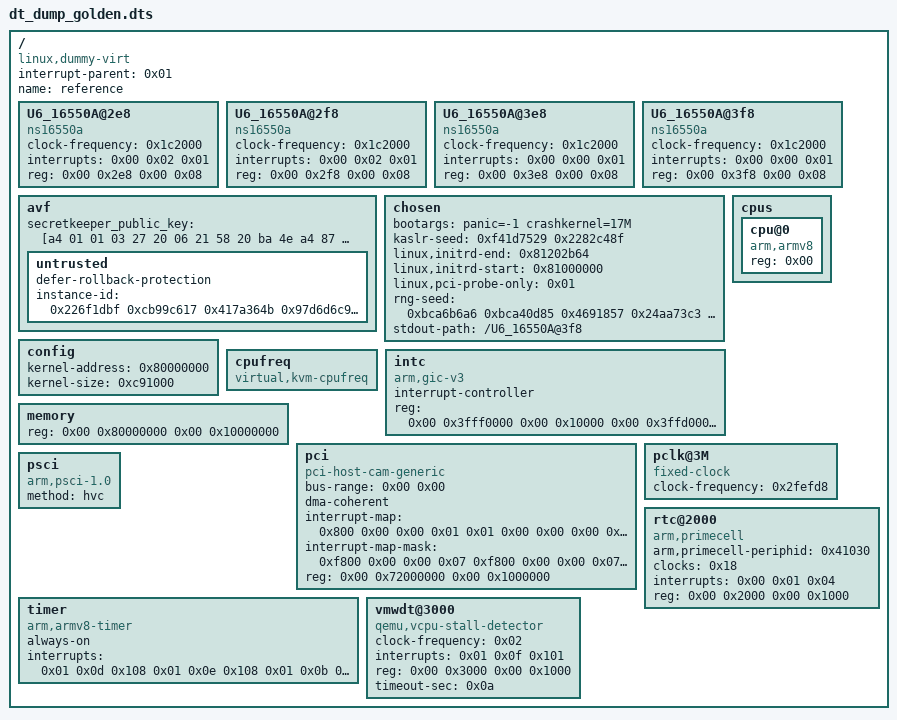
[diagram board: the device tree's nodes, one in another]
/dts-v1/;

/ {
	#address-cells = <0x02>;
	#size-cells = <0x02>;
	compatible = "linux,dummy-virt";
	interrupt-parent = <0x01>;
	name = "reference";

	U6_16550A@2e8 {
		clock-frequency = <0x1c2000>;
		compatible = "ns16550a";
		interrupts = <0x00 0x02 0x01>;
		reg = <0x00 0x2e8 0x00 0x08>;
	};

	U6_16550A@2f8 {
		clock-frequency = <0x1c2000>;
		compatible = "ns16550a";
		interrupts = <0x00 0x02 0x01>;
		reg = <0x00 0x2f8 0x00 0x08>;
	};

	U6_16550A@3e8 {
		clock-frequency = <0x1c2000>;
		compatible = "ns16550a";
		interrupts = <0x00 0x00 0x01>;
		reg = <0x00 0x3e8 0x00 0x08>;
	};

	U6_16550A@3f8 {
		clock-frequency = <0x1c2000>;
		compatible = "ns16550a";
		interrupts = <0x00 0x00 0x01>;
		reg = <0x00 0x3f8 0x00 0x08>;
	};

	__symbols__ {
		intc = "/intc";
	};

	avf {
		secretkeeper_public_key = [a4 01 01 03 27 20 06 21 58 20 ba 4e a4 87 1a 9e 8e 3b a9 15 f4 7c 02 89 87 bd c4 70 d7 b8 48 91 a1 09 38 83 20 c9 85 58 7d a8];

		untrusted {
			defer-rollback-protection;
			instance-id = <0x226f1dbf 0xcb99c617 0x417a364b 0x97d6d6c9 0x278098e 0x1ef0198d 0x5db1a290 0x601513f5 0xddac8bb5 0x9b1dad87 0xecfe9c66 0x7a97e57e 0x4a02c804 0x455207f7 0x766f9490 0x94f4c30d>;
		};
	};

	chosen {
		bootargs = "panic=-1 crashkernel=17M";
		kaslr-seed = <0xf41d7529 0x2282c48f>;
		linux,initrd-end = <0x81202b64>;
		linux,initrd-start = <0x81000000>;
		linux,pci-probe-only = <0x01>;
		rng-seed = <0xbca6b6a6 0xbca40d85 0x4691857 0x24aa73c3 0x2acd4d64 0x978184a3 0x34fedccc 0x18c5858e 0x89a0f436 0xa873b57e 0xbabdc555 0x94611b2f 0xf5c00896 0xaefc540 0xd50b30d3 0x444c020e 0xa55029f1 0xb589c657 0x9704b342 0xe3bcc3cd 0x128c7dac 0x1f0ee287 0xa447ac89 0x4a78e56 0x324b73b9 0x3a83eed3 0x771efcf1 0x7a7cc6bd 0xcd5912fc 0x28163d1b 0x38764934 0xb02ad6f8 0x89666e5c 0x92c6e112 0xb55f4739 0xa321da86 0x1726fabb 0x1b628c1c 0x5a3c1c5b 0xa5c1a2cb 0xace0e1ae 0x7a86e528 0xcafcdc24 0x73a6a268 0x72fbb9fc 0xca52c7c5 0xf540b2e9 0x14684a4c 0xfc88a4e 0x7dddde5d 0x22994ddd 0xf4a79d13 0x7149e07d 0xc5de64bd 0x50b35637 0xaef6cd2b 0x4210696f 0xc948145e 0xe4cce026 0xf50cbd5e 0xfcdf5ae5 0xc0120fe7 0x62b53fc6 0x31006531>;
		stdout-path = "/U6_16550A@3f8";
	};

	config {
		kernel-address = <0x80000000>;
		kernel-size = <0xc91000>;
	};

	cpufreq {
		compatible = "virtual,kvm-cpufreq";
	};

	cpus {
		#address-cells = <0x01>;
		#size-cells = <0x00>;

		cpu@0 {
			compatible = "arm,armv8";
			device_type = "cpu";
			phandle = <0x100>;
			reg = <0x00>;
		};
	};

	intc {
		#address-cells = <0x02>;
		#interrupt-cells = <0x03>;
		#size-cells = <0x02>;
		compatible = "arm,gic-v3";
		interrupt-controller;
		phandle = <0x01>;
		reg = <0x00 0x3fff0000 0x00 0x10000 0x00 0x3ffd0000 0x00 0x20000>;
	};

	memory {
		device_type = "memory";
		reg = <0x00 0x80000000 0x00 0x10000000>;
	};

	pci {
		#address-cells = <0x03>;
		#interrupt-cells = <0x01>;
		#size-cells = <0x02>;
		bus-range = <0x00 0x00>;
		compatible = "pci-host-cam-generic";
		device_type = "pci";
		dma-coherent;
		interrupt-map = <0x800 0x00 0x00 0x01 0x01 0x00 0x00 0x00 0x04 0x04 0x1000 0x00 0x00 0x01 0x01 0x00 0x00 0x00 0x05 0x04 0x1800 0x00 0x00 0x01 0x01 0x00 0x00 0x00 0x06 0x04 0x2000 0x00 0x00 0x01 0x01 0x00 0x00 0x00 0x07 0x04 0x2800 0x00 0x00 0x01 0x01 0x00 0x00 0x00 0x08 0x04 0x3000 0x00 0x00 0x01 0x01 0x00 0x00 0x00 0x09 0x04 0x3800 0x00 0x00 0x01 0x01 0x00 0x00 0x00 0x0a 0x04 0x4000 0x00 0x00 0x01 0x01 0x00 0x00 0x00 0x0b 0x04 0x4800 0x00 0x00 0x01 0x01 0x00 0x00 0x00 0x0c 0x04>;
		interrupt-map-mask = <0xf800 0x00 0x00 0x07 0xf800 0x00 0x00 0x07 0xf800 0x00 0x00 0x07 0xf800 0x00 0x00 0x07 0xf800 0x00 0x00 0x07 0xf800 0x00 0x00 0x07 0xf800 0x00 0x00 0x07 0xf800 0x00 0x00 0x07 0xf800 0x00 0x00 0x07>;
		ranges = <0x3000000 0x00 0x70000000 0x00 0x70000000 0x00 0x2000000 0x43000000 0x00 0x90800000 0x00 0x90800000 0xff 0x6f800000>;
		reg = <0x00 0x72000000 0x00 0x1000000>;
	};

	pclk@3M {
		#clock-cells = <0x00>;
		clock-frequency = <0x2fefd8>;
		compatible = "fixed-clock";
		phandle = <0x18>;
	};

	psci {
		compatible = "arm,psci-1.0\0arm,psci-0.2";
		method = "hvc";
	};

	rtc@2000 {
		arm,primecell-periphid = <0x41030>;
		clock-names = "apb_pclk";
		clocks = <0x18>;
		compatible = "arm,primecell";
		interrupts = <0x00 0x01 0x04>;
		reg = <0x00 0x2000 0x00 0x1000>;
	};

	timer {
		always-on;
		compatible = "arm,armv8-timer";
		interrupts = <0x01 0x0d 0x108 0x01 0x0e 0x108 0x01 0x0b 0x108 0x01 0x0a 0x108>;
	};

	vmwdt@3000 {
		clock-frequency = <0x02>;
		compatible = "qemu,vcpu-stall-detector";
		interrupts = <0x01 0x0f 0x101>;
		reg = <0x00 0x3000 0x00 0x1000>;
		timeout-sec = <0x0a>;
	};
};
